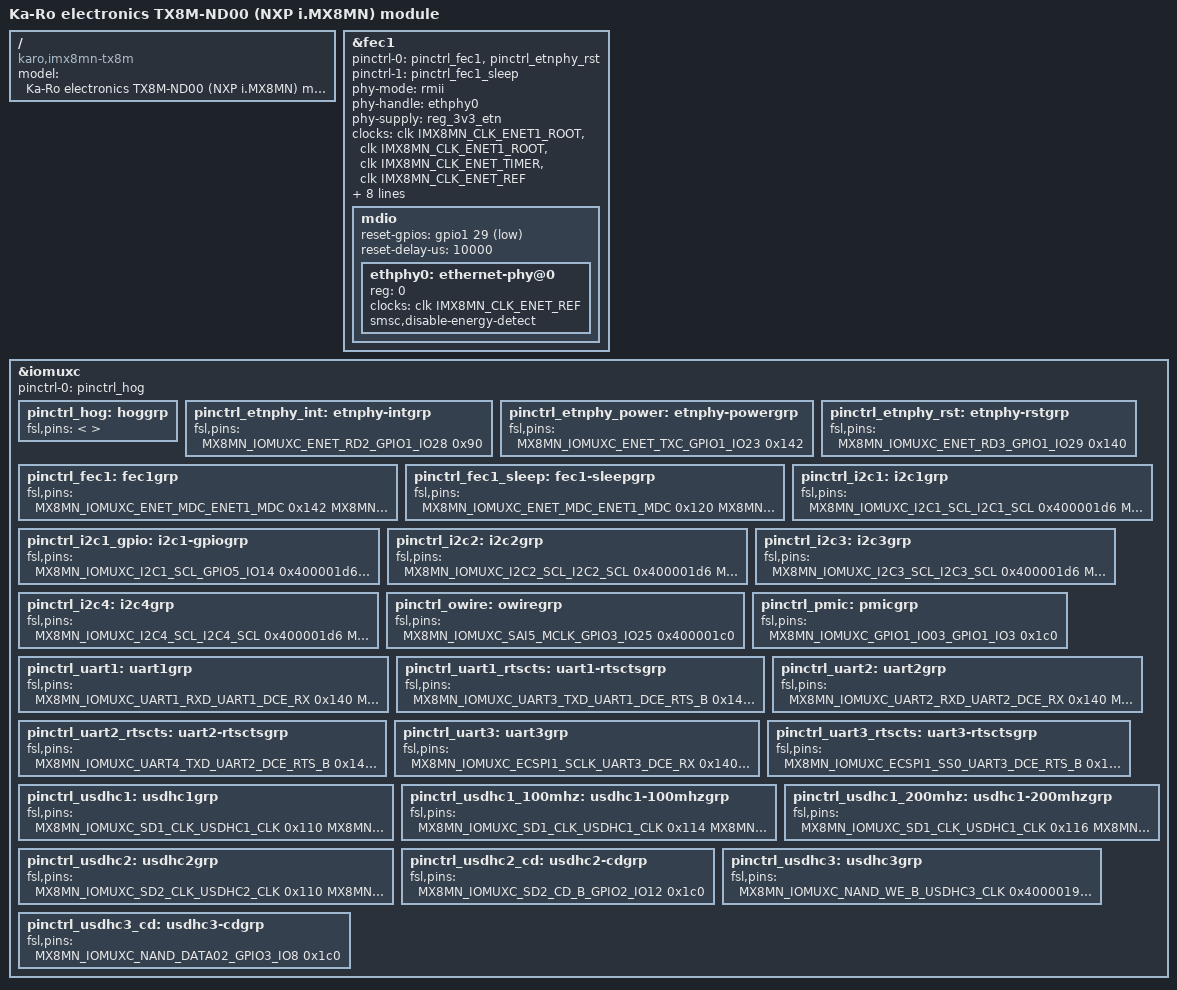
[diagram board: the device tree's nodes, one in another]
// SPDX-License-Identifier: (GPL-2.0 OR MIT)
/*
 * Copyright (C) 2019 Lothar Waßmann <LW@KARO-electronics.de>
 *
 */

/dts-v1/;

#include "imx8mn.dtsi"
#include "imx8m-tx8m.dtsi"

/ {
	model = "Ka-Ro electronics TX8M-ND00 (NXP i.MX8MN) module";
	compatible = "karo,imx8mn-tx8m", "fsl,imx8mn";
};

&fec1 {
	pinctrl-names = "default", "sleep";
	pinctrl-0 = <&pinctrl_fec1 &pinctrl_etnphy_rst>;
	pinctrl-1 = <&pinctrl_fec1_sleep>;
	phy-mode = "rmii";
	phy-handle = <&ethphy0>;
	phy-supply = <&reg_3v3_etn>;
	clocks = <&clk IMX8MN_CLK_ENET1_ROOT>,
		 <&clk IMX8MN_CLK_ENET1_ROOT>,
		 <&clk IMX8MN_CLK_ENET_TIMER>,
		 <&clk IMX8MN_CLK_ENET_REF>;
	assigned-clocks = <&clk IMX8MN_CLK_ENET_AXI>,
			  <&clk IMX8MN_CLK_ENET_TIMER>,
			  <&clk IMX8MN_CLK_ENET_REF>;
	assigned-clock-parents = <&clk IMX8MN_SYS_PLL1_266M>,
				 <&clk IMX8MN_SYS_PLL2_100M>,
				 <&clk IMX8MN_SYS_PLL2_50M>;
	assigned-clock-rates = <0>, <100000000>, <50000000>;
	status = "okay";

	mdio {
		#address-cells = <1>;
		#size-cells = <0>;
		reset-gpios = <&gpio1 29 GPIO_ACTIVE_LOW>;
		reset-delay-us = <10000>;

		ethphy0: ethernet-phy@0 {
			reg = <0>;
			clocks = <&clk IMX8MN_CLK_ENET_REF>;
			smsc,disable-energy-detect;
		};
	};
};

&iomuxc {
	pinctrl-names = "default";
	pinctrl-0 = <&pinctrl_hog>;

	pinctrl_hog: hoggrp {
		fsl,pins = <
		>;
	};

	pinctrl_etnphy_int: etnphy-intgrp {
		fsl,pins = <
			MX8MN_IOMUXC_ENET_RD2_GPIO1_IO28		0x90
		>;
	};

	pinctrl_etnphy_power: etnphy-powergrp {
		fsl,pins = <
			MX8MN_IOMUXC_ENET_TXC_GPIO1_IO23		0x142
		>;
	};

	pinctrl_etnphy_rst: etnphy-rstgrp {
		fsl,pins = <
			MX8MN_IOMUXC_ENET_RD3_GPIO1_IO29		0x140
		>;
	};

	pinctrl_fec1: fec1grp {
		fsl,pins = <
			MX8MN_IOMUXC_ENET_MDC_ENET1_MDC			0x142
			MX8MN_IOMUXC_ENET_MDIO_ENET1_MDIO		0x142
			MX8MN_IOMUXC_ENET_TD2_ENET1_TX_CLK		0x40000016
			MX8MN_IOMUXC_ENET_TD0_ENET1_RGMII_TD0		0x16
			MX8MN_IOMUXC_ENET_TD1_ENET1_RGMII_TD1		0x16
			MX8MN_IOMUXC_ENET_RD0_ENET1_RGMII_RD0		0x90
			MX8MN_IOMUXC_ENET_RD1_ENET1_RGMII_RD1		0x90
			MX8MN_IOMUXC_ENET_RXC_ENET1_RX_ER		0x16
			MX8MN_IOMUXC_ENET_RX_CTL_ENET1_RGMII_RX_CTL	0x16
			MX8MN_IOMUXC_ENET_TX_CTL_ENET1_RGMII_TX_CTL	0x16
		>;
	};

	pinctrl_fec1_sleep: fec1-sleepgrp {
		fsl,pins = <
			MX8MN_IOMUXC_ENET_MDC_ENET1_MDC			0x120
			MX8MN_IOMUXC_ENET_MDIO_ENET1_MDIO		0x120
			MX8MN_IOMUXC_ENET_TD0_ENET1_RGMII_TD0		0x120
			MX8MN_IOMUXC_ENET_TD1_ENET1_RGMII_TD1		0x120
			MX8MN_IOMUXC_ENET_RD0_ENET1_RGMII_RD0		0x120
			MX8MN_IOMUXC_ENET_RD1_ENET1_RGMII_RD1		0x120
			MX8MN_IOMUXC_ENET_RXC_ENET1_RX_ER		0x120
			MX8MN_IOMUXC_ENET_RX_CTL_ENET1_RGMII_RX_CTL	0x120
			MX8MN_IOMUXC_ENET_TX_CTL_ENET1_RGMII_TX_CTL	0x120
		>;
	};

	pinctrl_i2c1: i2c1grp {
		fsl,pins = <
			MX8MN_IOMUXC_I2C1_SCL_I2C1_SCL			0x400001d6
			MX8MN_IOMUXC_I2C1_SDA_I2C1_SDA			0x400001d6
		>;
	};

	pinctrl_i2c1_gpio: i2c1-gpiogrp {
		fsl,pins = <
			MX8MN_IOMUXC_I2C1_SCL_GPIO5_IO14		0x400001d6
			MX8MN_IOMUXC_I2C1_SDA_GPIO5_IO15		0x400001d6
		>;
	};

	pinctrl_i2c2: i2c2grp {
		fsl,pins = <
			MX8MN_IOMUXC_I2C2_SCL_I2C2_SCL			0x400001d6
			MX8MN_IOMUXC_I2C2_SDA_I2C2_SDA			0x400001d6
		>;
	};

	pinctrl_i2c3: i2c3grp {
		fsl,pins = <
			MX8MN_IOMUXC_I2C3_SCL_I2C3_SCL			0x400001d6
			MX8MN_IOMUXC_I2C3_SDA_I2C3_SDA			0x400001d6
		>;
	};

	pinctrl_i2c4: i2c4grp {
		fsl,pins = <
			MX8MN_IOMUXC_I2C4_SCL_I2C4_SCL			0x400001d6
			MX8MN_IOMUXC_I2C4_SDA_I2C4_SDA			0x400001d6
		>;
	};

	pinctrl_owire: owiregrp {
		fsl,pins = <
			MX8MN_IOMUXC_SAI5_MCLK_GPIO3_IO25		0x400001c0
		>;
	};

	pinctrl_pmic: pmicgrp {
		fsl,pins = <
			MX8MN_IOMUXC_GPIO1_IO03_GPIO1_IO3		0x1c0
		>;
	};

	pinctrl_uart1: uart1grp {
		fsl,pins = <
			MX8MN_IOMUXC_UART1_RXD_UART1_DCE_RX		0x140
			MX8MN_IOMUXC_UART1_TXD_UART1_DCE_TX		0x140
		>;
	};

	pinctrl_uart1_rtscts: uart1-rtsctsgrp {
		fsl,pins = <
			MX8MN_IOMUXC_UART3_TXD_UART1_DCE_RTS_B		0x140
			MX8MN_IOMUXC_UART3_RXD_UART1_DCE_CTS_B		0x140
		>;
	};

	pinctrl_uart2: uart2grp {
		fsl,pins = <
			MX8MN_IOMUXC_UART2_RXD_UART2_DCE_RX		0x140
			MX8MN_IOMUXC_UART2_TXD_UART2_DCE_TX		0x140
		>;
	};

	pinctrl_uart2_rtscts: uart2-rtsctsgrp {
		fsl,pins = <
			MX8MN_IOMUXC_UART4_TXD_UART2_DCE_RTS_B		0x140
			MX8MN_IOMUXC_UART4_RXD_UART2_DCE_CTS_B		0x140
		>;
	};

	pinctrl_uart3: uart3grp {
		fsl,pins = <
			MX8MN_IOMUXC_ECSPI1_SCLK_UART3_DCE_RX		0x140
			MX8MN_IOMUXC_ECSPI1_MOSI_UART3_DCE_TX		0x140
		>;
	};

	pinctrl_uart3_rtscts: uart3-rtsctsgrp {
		fsl,pins = <
			MX8MN_IOMUXC_ECSPI1_SS0_UART3_DCE_RTS_B		0x140
			MX8MN_IOMUXC_ECSPI1_MISO_UART3_DCE_CTS_B	0x140
		>;
	};

	pinctrl_usdhc1: usdhc1grp {
		fsl,pins = <
			MX8MN_IOMUXC_SD1_CLK_USDHC1_CLK			0x110
			MX8MN_IOMUXC_SD1_CMD_USDHC1_CMD			0x150
			MX8MN_IOMUXC_SD1_DATA0_USDHC1_DATA0		0x150
			MX8MN_IOMUXC_SD1_DATA1_USDHC1_DATA1		0x150
			MX8MN_IOMUXC_SD1_DATA2_USDHC1_DATA2		0x150
			MX8MN_IOMUXC_SD1_DATA3_USDHC1_DATA3		0x150
			MX8MN_IOMUXC_SD1_DATA4_USDHC1_DATA4		0x150
			MX8MN_IOMUXC_SD1_DATA5_USDHC1_DATA5		0x150
			MX8MN_IOMUXC_SD1_DATA6_USDHC1_DATA6		0x150
			MX8MN_IOMUXC_SD1_DATA7_USDHC1_DATA7		0x150
			MX8MN_IOMUXC_SD1_STROBE_USDHC1_STROBE		0x156
			MX8MN_IOMUXC_SD1_RESET_B_USDHC1_RESET_B		0x156
		>;
	};

	pinctrl_usdhc1_100mhz: usdhc1-100mhzgrp {
		fsl,pins = <
			MX8MN_IOMUXC_SD1_CLK_USDHC1_CLK			0x114
			MX8MN_IOMUXC_SD1_CMD_USDHC1_CMD			0x154
			MX8MN_IOMUXC_SD1_DATA0_USDHC1_DATA0		0x154
			MX8MN_IOMUXC_SD1_DATA1_USDHC1_DATA1		0x154
			MX8MN_IOMUXC_SD1_DATA2_USDHC1_DATA2		0x154
			MX8MN_IOMUXC_SD1_DATA3_USDHC1_DATA3		0x154
			MX8MN_IOMUXC_SD1_DATA4_USDHC1_DATA4		0x154
			MX8MN_IOMUXC_SD1_DATA5_USDHC1_DATA5		0x154
			MX8MN_IOMUXC_SD1_DATA6_USDHC1_DATA6		0x154
			MX8MN_IOMUXC_SD1_DATA7_USDHC1_DATA7		0x154
			MX8MN_IOMUXC_SD1_STROBE_USDHC1_STROBE		0x156
			MX8MN_IOMUXC_SD1_RESET_B_USDHC1_RESET_B		0x156
		>;
	};

	pinctrl_usdhc1_200mhz: usdhc1-200mhzgrp {
		fsl,pins = <
			MX8MN_IOMUXC_SD1_CLK_USDHC1_CLK			0x116
			MX8MN_IOMUXC_SD1_CMD_USDHC1_CMD			0x156
			MX8MN_IOMUXC_SD1_DATA0_USDHC1_DATA0		0x156
			MX8MN_IOMUXC_SD1_DATA1_USDHC1_DATA1		0x156
			MX8MN_IOMUXC_SD1_DATA2_USDHC1_DATA2		0x156
			MX8MN_IOMUXC_SD1_DATA3_USDHC1_DATA3		0x156
			MX8MN_IOMUXC_SD1_DATA4_USDHC1_DATA4		0x156
			MX8MN_IOMUXC_SD1_DATA5_USDHC1_DATA5		0x156
			MX8MN_IOMUXC_SD1_DATA6_USDHC1_DATA6		0x156
			MX8MN_IOMUXC_SD1_DATA7_USDHC1_DATA7		0x156
			MX8MN_IOMUXC_SD1_STROBE_USDHC1_STROBE		0x156
			MX8MN_IOMUXC_SD1_RESET_B_USDHC1_RESET_B		0x156
		>;
	};

	pinctrl_usdhc2: usdhc2grp {
		fsl,pins = <
			MX8MN_IOMUXC_SD2_CLK_USDHC2_CLK			0x110
			MX8MN_IOMUXC_SD2_CMD_USDHC2_CMD			0x150
			MX8MN_IOMUXC_SD2_DATA0_USDHC2_DATA0		0x150
			MX8MN_IOMUXC_SD2_DATA1_USDHC2_DATA1		0x150
			MX8MN_IOMUXC_SD2_DATA2_USDHC2_DATA2		0x150
			MX8MN_IOMUXC_SD2_DATA3_USDHC2_DATA3		0x150
		>;
	};

	pinctrl_usdhc2_cd: usdhc2-cdgrp {
		fsl,pins = <
			MX8MN_IOMUXC_SD2_CD_B_GPIO2_IO12		0x1c0
		>;
	};

	pinctrl_usdhc3: usdhc3grp {
		fsl,pins = <
			/*
			 * Erratum e11341: SION must be asserted on NAND_WE_B
			 * when used as SDHC3_CLK
			 */
			MX8MN_IOMUXC_NAND_WE_B_USDHC3_CLK		0x40000190
			MX8MN_IOMUXC_NAND_WP_B_USDHC3_CMD		0x1d0
			MX8MN_IOMUXC_NAND_DATA04_USDHC3_DATA0		0x1d0
			MX8MN_IOMUXC_NAND_DATA05_USDHC3_DATA1		0x1d0
			MX8MN_IOMUXC_NAND_DATA06_USDHC3_DATA2		0x1d0
			MX8MN_IOMUXC_NAND_DATA07_USDHC3_DATA3		0x1d0
		>;
	};

	pinctrl_usdhc3_cd: usdhc3-cdgrp {
		fsl,pins = <
			MX8MN_IOMUXC_NAND_DATA02_GPIO3_IO8		0x1c0
		>;
	};
};
